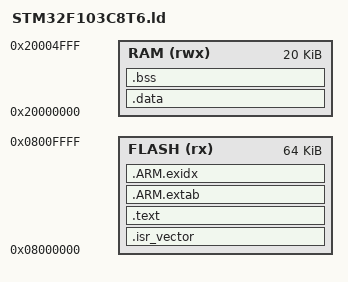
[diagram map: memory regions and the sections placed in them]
/*
 * Linker script for STM32F103C8T6 (64KB Flash, 20KB RAM)
 * For ARM GCC toolchain
 */

ENTRY(Reset_Handler)

MEMORY
{
    FLASH (rx) : ORIGIN = 0x08000000, LENGTH = 64K
    RAM   (rwx) : ORIGIN = 0x20000000, LENGTH = 20K
}

_estack = ORIGIN(RAM) + LENGTH(RAM);

SECTIONS
{
    /* Vector table and code */
    .isr_vector :
    {
        . = ALIGN(4);
        KEEP(*(.isr_vector))
        . = ALIGN(4);
    } > FLASH

    .text :
    {
        . = ALIGN(4);
        *(.text)
        *(.text*)
        *(.rodata)
        *(.rodata*)
        *(.glue_7)
        *(.glue_7t)
        . = ALIGN(4);
        _etext = .;
    } > FLASH

    /* ARM exception unwinding */
    .ARM.extab :
    {
        *(.ARM.extab* .gnu.linkonce.armextab.*)
    } > FLASH

    .ARM.exidx :
    {
        __exidx_start = .;
        *(.ARM.exidx* .gnu.linkonce.armexidx.*)
        __exidx_end = .;
    } > FLASH

    _sidata = .;

    /* Initialized data */
    .data : AT(_sidata)
    {
        . = ALIGN(4);
        _sdata = .;
        *(.data)
        *(.data*)
        . = ALIGN(4);
        _edata = .;
    } > RAM

    /* Uninitialized data (BSS) */
    .bss :
    {
        . = ALIGN(4);
        _sbss = .;
        *(.bss)
        *(.bss*)
        *(COMMON)
        . = ALIGN(4);
        _ebss = .;
    } > RAM

    /* End of heap marker for sbrk */
    . = ALIGN(4);
    end = .;
    _end = .;
}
